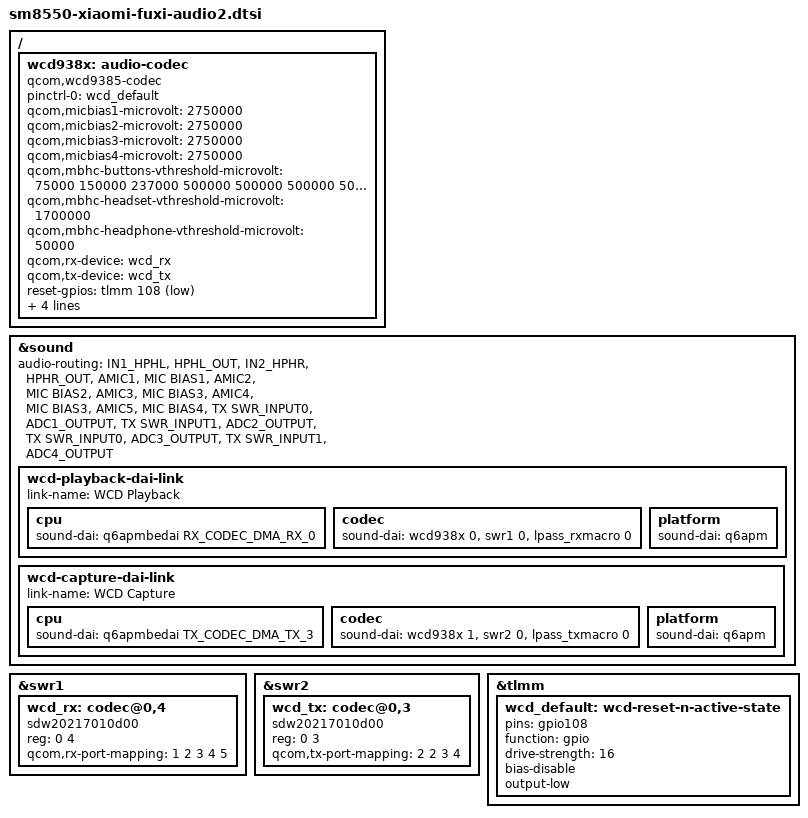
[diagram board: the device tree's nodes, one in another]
// SPDX-License-Identifier: BSD-3-Clause
/*
 * Xiaomi 13 (fuxi)：音频变体第二步 = 第一步（两个扬声器）+ WCD9385 编解码器（麦克风、USB-C 模拟耳机）。
 * 厂商 DTB 里 WCD938x 的接法与 SM8550 QRD 相同：复位 GPIO108、vdd-buck/rxtx/io = L15B 1.8V、
 * micbias = BOB1，SoundWire RX（swr1）从设备 0x...224、TX（swr2）从设备 0x...223。
 * 区别：micbias 2.75V（厂商 qcom,cdc-micbias*-mv = 2750）；数字麦克风引脚组在厂商 DTB 里都是 disabled，
 * 麦克风全是 WCD 的模拟输入（AMIC1..5），走 TX 宏 TX_CODEC_DMA_TX_3（拓扑里 QRD 原有的 WCD Capture 通路）。
 * USB-C 耳机还需要 FSA4480 类切换芯片 + pmic_glink 的 USB-C connector（后续）。
 *
 * 构建：FUXI_DTB=sm8550-xiaomi-fuxi-audio2 scripts/fuxi-build-abl.sh <名字>
 */


/ {
	wcd938x: audio-codec {
		compatible = "qcom,wcd9385-codec";

		pinctrl-0 = <&wcd_default>;
		pinctrl-names = "default";

		qcom,micbias1-microvolt = <2750000>;
		qcom,micbias2-microvolt = <2750000>;
		qcom,micbias3-microvolt = <2750000>;
		qcom,micbias4-microvolt = <2750000>;
		qcom,mbhc-buttons-vthreshold-microvolt = <75000 150000 237000 500000 500000 500000 500000 500000>;
		qcom,mbhc-headset-vthreshold-microvolt = <1700000>;
		qcom,mbhc-headphone-vthreshold-microvolt = <50000>;
		qcom,rx-device = <&wcd_rx>;
		qcom,tx-device = <&wcd_tx>;

		reset-gpios = <&tlmm 108 GPIO_ACTIVE_LOW>;

		vdd-buck-supply = <&vreg_l15b_1p8>;
		vdd-rxtx-supply = <&vreg_l15b_1p8>;
		vdd-io-supply = <&vreg_l15b_1p8>;
		vdd-mic-bias-supply = <&vreg_bob1>;

		#sound-dai-cells = <1>;
	};
};

&sound {
	/* 厂商 qcom,audio-routing 里与 WCD 模拟麦克风/耳机相关的部分 */
	audio-routing = "IN1_HPHL", "HPHL_OUT",
			"IN2_HPHR", "HPHR_OUT",
			"AMIC1", "MIC BIAS1",
			"AMIC2", "MIC BIAS2",
			"AMIC3", "MIC BIAS3",
			"AMIC4", "MIC BIAS3",
			"AMIC5", "MIC BIAS4",
			"TX SWR_INPUT0", "ADC1_OUTPUT",
			"TX SWR_INPUT1", "ADC2_OUTPUT",
			"TX SWR_INPUT0", "ADC3_OUTPUT",
			"TX SWR_INPUT1", "ADC4_OUTPUT";

	wcd-playback-dai-link {
		link-name = "WCD Playback";

		cpu {
			sound-dai = <&q6apmbedai RX_CODEC_DMA_RX_0>;
		};

		codec {
			sound-dai = <&wcd938x 0>, <&swr1 0>, <&lpass_rxmacro 0>;
		};

		platform {
			sound-dai = <&q6apm>;
		};
	};

	wcd-capture-dai-link {
		link-name = "WCD Capture";

		cpu {
			sound-dai = <&q6apmbedai TX_CODEC_DMA_TX_3>;
		};

		codec {
			sound-dai = <&wcd938x 1>, <&swr2 0>, <&lpass_txmacro 0>;
		};

		platform {
			sound-dai = <&q6apm>;
		};
	};
};

&swr1 {
	status = "okay";

	/* WCD9385 RX */
	wcd_rx: codec@0,4 {
		compatible = "sdw20217010d00";
		reg = <0 4>;
		qcom,rx-port-mapping = <1 2 3 4 5>;
	};
};

&swr2 {
	status = "okay";

	/* WCD9385 TX */
	wcd_tx: codec@0,3 {
		compatible = "sdw20217010d00";
		reg = <0 3>;
		qcom,tx-port-mapping = <2 2 3 4>;
	};
};

&tlmm {
	/* 厂商 wcd938x_reset_active：GPIO108 */
	wcd_default: wcd-reset-n-active-state {
		pins = "gpio108";
		function = "gpio";
		drive-strength = <16>;
		bias-disable;
		output-low;
	};
};
